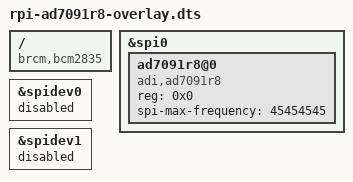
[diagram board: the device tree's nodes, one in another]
// SPDX-License-Identifier: GPL-2.0

/dts-v1/;
/plugin/;

/ {
	compatible = "brcm,bcm2835", "brcm,bcm2711";
};

&spi0 {
	status = "okay";

	ad7091r8@0 {
		compatible = "adi,ad7091r8";
		reg = <0x0>;
		spi-max-frequency = <45454545>;
		status = "okay";
	};
};

&spidev0 {
	status = "disabled";
};

&spidev1 {
	status = "disabled";
};
